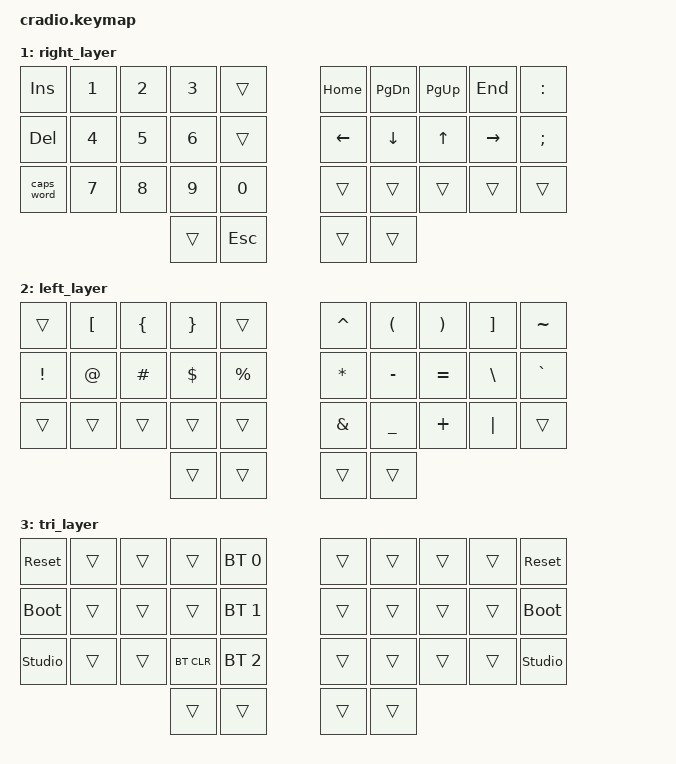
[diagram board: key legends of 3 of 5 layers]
// Copyright (c) 2022 The ZMK Contributors
// SPDX-License-Identifier: MIT

#include <behaviors.dtsi>
#include <dt-bindings/zmk/keys.h>
#include <dt-bindings/zmk/bt.h>
#include <dt-bindings/zmk/pointing.h>

// Home row mods macro
#define HRML(k1,k2,k3,k4) &ht LSHFT k1  &ht LALT k2  &ht LCTRL k3  &ht LGUI k4
#define HRMR(k1,k2,k3,k4) &ht RGUI k1  &ht RCTRL k2  &ht RALT k3  &ht RSHFT k4

// Keep sticky keys active for a long time so they effectively do not time out


&mt {
    //  flavor = "tap-preferred";
    // tapping_term_ms = <200>;
};

#define LEFT_HYPER LS(LC(LA(LGUI)))
#define LH(key) LS(LC(LA(LG(key))))
#define LHYPER LEFT_HYPER
#define OFFICE LEFT_HYPER

#define LEFT_MEH LS(LC(LALT))
#define LM(key) LS(LC(LA(key)))
#define LMEH LEFT_MEH


#define LEFT_ULTRA LG(LC(LALT))
#define LU(key) LG(LC(LA(key)))
#define LULTRA LEFT_ULTRA

#define RIGHT_HYPER RS(RC(RA(RGUI)))
#define RH(key) RS(RC(RA(RG(key))))
#define RHYPER RIGHT_HYPER

#define RIGHT_MEH RS(RC(RALT))
#define RM(key) RS(RC(RA(key)))
#define RMEH RIGHT_MEH


#define RIGHT_ULTRA RG(RC(RALT))
#define RU(key) RG(RC(RA(key)))
#define RULTRA RIGHT_ULTRA

#define STICKY_KEY_TIMEOUT 60000

&sk {
    release-after-ms = <STICKY_KEY_TIMEOUT>;

    /delete-property/ ignore-modifiers;
};

/ {
    behaviors {
        ht: hold_tap {
            compatible = "zmk,behavior-hold-tap";
            #binding-cells = <2>;
            flavor = "tap-preferred";
            tapping-term-ms = <220>;
            quick-tap-ms = <150>;
            require-prior-idle-ms = <100>;
            bindings = <&kp>, <&kp>;
        };
    };

    conditional_layers {
        compatible = "zmk,conditional-layers";
        tri_layer {
            if-layers = <1 2>;
            then-layer = <3>;
        };
    };

    keymap {
        compatible = "zmk,keymap";
        default_layer {
            bindings = <
        //╭──────────┬──────────┬──────────┬──────────┬──────────╮   ╭──────────┬──────────┬──────────┬──────────┬──────────╮
        //│  Q       │  W       │  E       │  R       │  T       │   │  Y       │  U       │  I       │  O       │  P       │
          &mt RULTRA Q &mt RMEH W &mt RHYPER E &kp R    &kp T          &kp Y      &kp U    &mt LHYPER I &mt LMEH O &mt LULTRA P
        //├──────────┼──────────┼──────────┼──────────┼──────────┤   ├──────────┼──────────┼──────────┼──────────┼──────────┤
        //│  A       │  S       │  D       │  F       │  G       │   │  H       │  J       │  K       │  L       │ ' "      │
            HRML(A,        S,         D,         F)     &kp G          &kp H      HRMR(J,        K,         L,        SQT)
        //├──────────┼──────────┼──────────┼──────────┼──────────┤   ├──────────┼──────────┼──────────┼──────────┼──────────┤
        //│  Z       │  X       │  C       │  V       │  B       │   │  N       │  M       │ , <      │ . >      │ / ?      │
            &kp Z      &kp X      &kp C      &kp V      &kp B          &kp N      &kp M      &kp COMMA  &kp DOT    &kp FSLH
        //╰──────────┴──────────┴──────────┼──────────┼──────────┤   ├──────────┼──────────┼──────────┴──────────┴──────────╯
                                             &lt 2 TAB   &lt 4 ENTER     &kp SPACE  &lt 1 BSPC
        //                                 ╰──────────┴──────────╯   ╰──────────┴──────────╯
            >;
        };

        right_layer {
            bindings = <
        //╭──────────┬──────────┬──────────┬──────────┬──────────╮   ╭──────────┬──────────┬──────────┬──────────┬──────────╮
        //│ INSERT   │  1       │  2       │  3       │          │   │ HOME     │ PAGE DN  │ PAGE UP  │ END      │  :       │
            &kp INS    &kp N1     &kp N2     &kp N3     &trans         &kp HOME   &kp PG_DN  &kp PG_UP  &kp END    &kp COLON
        //├──────────┼──────────┼──────────┼──────────┼──────────┤   ├──────────┼──────────┼──────────┼──────────┼──────────┤
        //│ DELETE   │  4       │  5       │  6       │          │   │ LEFT     │ DOWN     │ UP       │ RIGHT    │  ;       │
            &kp DEL    &kp N4     &kp N5     &kp N6     &trans         &kp LEFT   &kp DOWN   &kp UP   &kp RIGHT   &kp SEMI
        //├──────────┼──────────┼──────────┼──────────┼──────────┤   ├──────────┼──────────┼──────────┼──────────┼──────────┤
        //│ CAPS     │  7       │  8       │  9       │  0       │   │          │          │          │          │          │
           &caps_word  &kp N7     &kp N8     &kp N9     &kp N0         &trans     &trans     &trans     &trans     &trans
        //╰──────────┴──────────┴──────────┼──────────┼──────────┤   ├──────────┼──────────┼──────────┴──────────┴──────────╯
                                             &trans     &kp ESC        &trans     &trans
        //                                 ╰──────────┴──────────╯   ╰──────────┴──────────╯
            >;
        };

        left_layer {
            bindings = <
        //╭──────────┬──────────┬──────────┬──────────┬──────────╮   ╭──────────┬──────────┬──────────┬──────────┬──────────╮
        //│          │  [       │  {       │  }       │          │   │  ^       │  (       │  )       │  ]       │  ~       │
            &trans     &kp LBKT   &kp LBRC   &kp RBRC   &trans         &kp CARET  &kp LPAR   &kp RPAR   &kp RBKT   &kp TILDE
        //├──────────┼──────────┼──────────┼──────────┼──────────┤   ├──────────┼──────────┼──────────┼──────────┼──────────┤
        //│  !       │  @       │  #       │  $       │  %       │   │  *       │  -       │  =       │  \       │  `       │
            &kp EXCL   &kp AT     &kp HASH   &kp DLLR   &kp PRCNT      &kp ASTRK  &kp MINUS  &kp EQUAL  &kp BSLH   &kp GRAVE
        //├──────────┼──────────┼──────────┼──────────┼──────────┤   ├──────────┼──────────┼──────────┼──────────┼──────────┤
        //│          │          │          │          │          │   │  &       │  _       │  +       │  │       │          │
            &trans     &trans     &trans     &trans     &trans         &kp AMPS   &kp UNDER  &kp PLUS   &kp PIPE   &trans
        //╰──────────┴──────────┴──────────┼──────────┼──────────┤   ├──────────┼──────────┼──────────┴──────────┴──────────╯
                                             &trans     &trans         &trans     &trans
        //                                 ╰──────────┴──────────╯   ╰──────────┴──────────╯
            >;
        };

         tri_layer {
             bindings = <
         //╭──────────┬──────────┬──────────┬──────────┬──────────╮   ╭──────────┬──────────┬──────────┬──────────┬──────────╮
         //│ RESET    │          │          │          │PROFILE 0 │   │          │          │          │          │  RESET   │
            &sys_reset  &trans     &trans     &trans    &bt BT_SEL 0    &trans     &trans     &trans     &trans    &sys_reset
         //├──────────┼──────────┼──────────┼──────────┼──────────┤   ├──────────┼──────────┼──────────┼──────────┼──────────┤
         //│BOOTLOADER│          │          │          │PROFILE 1 │   │          │          │          │          │BOOTLOADER│
           &bootloader  &trans     &trans     &trans    &bt BT_SEL 1    &trans     &trans     &trans     &trans    &bootloader
         //├──────────┼──────────┼──────────┼──────────┼──────────┤   ├──────────┼──────────┼──────────┼──────────┼──────────┤
         //│          │          │          │ CLEAR BT │PROFILE 2 │   │          │          │          │          │          │
         &studio_unlock &trans     &trans    &bt BT_CLR &bt BT_SEL 2    &trans     &trans     &trans     &trans    &studio_unlock
         //╰──────────┴──────────┴──────────┼──────────┼──────────┤   ├──────────┼──────────┼──────────┴──────────┴──────────╯
                                              &trans     &trans         &trans     &trans
         //                                 ╰──────────┴──────────╯   ╰──────────┴──────────╯
              >;
          };

         mouse_layer {
             bindings = <
          //╭──────────┬──────────┬──────────┬──────────┬──────────╮   ╭──────────┬──────────┬──────────┬──────────┬──────────╮
          //│          │SCRL_LEFT │ SCRL_UP  │SCRL_RIGHT│          │   │  BTN5    │  BTN4    │   UP     │          │          │
             &trans     &msc SCRL_LEFT &msc SCRL_UP &msc SCRL_RIGHT &trans &mkp MB5 &mkp MB4 &mmv MOVE_UP &trans &trans &trans
         //├──────────┼──────────┼──────────┼──────────┼──────────┤   ├──────────┼──────────┼──────────┼──────────┼──────────┤
         //│          │  LCLK    │SCRL_DOWN │  RCLK    │          │   │          │  LEFT    │  DOWN    │  RIGHT   │          │
            &trans     &mkp MB1 &msc SCRL_DOWN &mkp MB2 &trans         &trans     &mmv MOVE_LEFT &mmv MOVE_DOWN &mmv MOVE_RIGHT &trans
         //├──────────┼──────────┼──────────┼──────────┼──────────┤   ├──────────┼──────────┼──────────┼──────────┼──────────┤
         //│          │          │          │          │          │   │          │          │          │          │          │
            &trans     &trans     &trans     &trans     &trans         &trans     &trans     &trans     &trans     &trans
         //╰──────────┴──────────┴──────────┼──────────┼──────────┤   ├──────────┼──────────┼──────────┴──────────┴──────────╯
                                              &trans     &trans         &trans     &trans
         //                                 ╰──────────┴──────────╯   ╰──────────┴──────────╯
             >;
         };
      };
};
